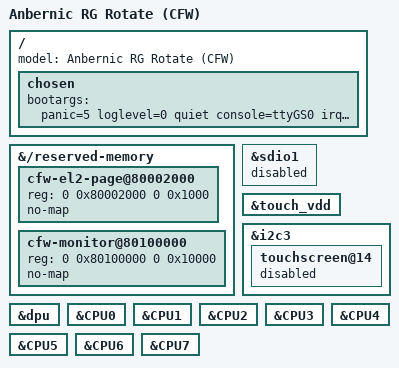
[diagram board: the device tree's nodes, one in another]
// SPDX-License-Identifier: (GPL-2.0 OR MIT)
/*
 * Anbernic RG Rotate, standalone CFW boot: the SPL loads the kernel straight
 * from eMMC with no SML/TOS secure world and no u-boot. Everything that only
 * existed for those (and for the modem/wcn, which this build does not use) is
 * handed back to Linux. The audio carveouts and pm_sys regions stay; they live
 * in ums512.dtsi.
 */

#include "ums512-rg-rotate.dts"

/ {
	model = "Anbernic RG Rotate (CFW)";

	/* No bootloader to supply a command line.
	 * dmesg is read over the USB serial. panic=5: once sprd_wdt
	 * owns the watchdog a panic would halt forever; reboot through the
	 * sc27xx restart handler instead. */
	chosen {
		bootargs = "panic=5 loglevel=0 quiet console=ttyGS0 irqchip.gicv3_pseudo_nmi=1";
	};

	/* PSCI comes from the SPL-loaded EL3 monitor (ext/boot/spl/monitor),
	 * which has no CPU_SUSPEND: no idle states. */
	/delete-node/ idle-states;
};

&{/reserved-memory} {
	/delete-node/ cp-mem@89600000;
	/delete-node/ sipc-mem@8e000000;
	/delete-node/ iq-mem@90000000;
	/delete-node/ sml-mem@94000000;
	/delete-node/ tos-mem@94040000;
	/delete-node/ sh-mem@9a000000;
	/delete-node/ uboot-log@9de80000;
	/delete-node/ framebuffer-region@9e000000;
	/delete-node/ logobuffer-tail@9e1fa400;
	/delete-node/ sysdump-uboot@9f000000;
	/delete-node/ widevine-mem@e3800000;
	/delete-node/ faceid-mem@fd270000;
	/delete-node/ vdsp-mem@fd770000;
	/delete-node/ rebootescrow@fff70000;

	/* SPL's EL2 entry stub and boot records (linux_entry.S); must match
	 * the SPL. */
	cfw-el2-page@80002000 {
		reg = <0 0x80002000 0 0x1000>;
		no-map;
	};

	/* EL3 monitor (PSCI): code, stacks, and a status page at +0xf000.
	 * Must match CFW_MON_BASE in the SPL. */
	cfw-monitor@80100000 {
		reg = <0 0x80100000 0 0x10000>;
		no-map;
	};
};

/* SDIO wifi (mmc1): unused on the CFW, and with no u-boot to power the
 * module it floods the console with SDHCI register dumps. SD stays on sdio0. */
&sdio1 {
	status = "disabled";
};

/* No touch input on the CFW (CONFIG_INPUT_TOUCHSCREEN is off): keep the
 * GT911 unbound and its supply off from probe, instead of on until the
 * unused-regulator cleanup ~30s in. */
&touch_vdd {
	/delete-property/ regulator-boot-on;
};

&i2c3 {
	touchscreen@14 {
		status = "disabled";
	};
};

/* The panel is brought up cold by the kernel, with no splash to inherit. */
&dpu {
	/delete-property/ memory-region;
};

&CPU0 {
	/delete-property/ cpu-idle-states;
};

&CPU1 {
	/delete-property/ cpu-idle-states;
};

&CPU2 {
	/delete-property/ cpu-idle-states;
};

&CPU3 {
	/delete-property/ cpu-idle-states;
};

&CPU4 {
	/delete-property/ cpu-idle-states;
};

&CPU5 {
	/delete-property/ cpu-idle-states;
};

&CPU6 {
	/delete-property/ cpu-idle-states;
};

&CPU7 {
	/delete-property/ cpu-idle-states;
};
